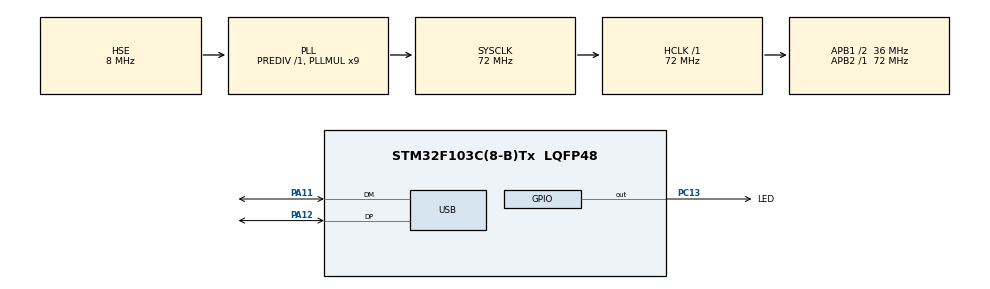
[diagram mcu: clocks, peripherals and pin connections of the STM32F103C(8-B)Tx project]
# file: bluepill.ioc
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FREERTOS.Tasks01=defaultTask,0,128,StartDefaultTask,Default,NULL
Mcu.Family=STM32F1
Mcu.Name=STM32F103C(8-B)Tx
Mcu.Package=LQFP48
NVIC.PriorityGroup=NVIC_PRIORITYGROUP_4
NVIC.TIM1_UP_IRQn=true\:0\:0\:false\:false\:true\:false\:false\:true
NVIC.TimeBase=TIM1_UP_IRQn
NVIC.TimeBaseIP=TIM1
NVIC.USB_LP_CAN1_RX0_IRQn=true\:5\:0\:false\:false\:true\:true\:false\:true
PA11.Mode=Device
PA11.Signal=USB_DM
PA12.Mode=Device
PA12.Signal=USB_DP
PC13-TAMPER-RTC.GPIO_Label=LED
PC13-TAMPER-RTC.Signal=GPIO_Output
PC14-OSC32_IN.Mode=LSE-External-Oscillator
PC14-OSC32_IN.Signal=RCC_OSC32_IN
PC15-OSC32_OUT.Mode=LSE-External-Oscillator
PC15-OSC32_OUT.Signal=RCC_OSC32_OUT
PD0-OSC_IN.Mode=HSE-External-Oscillator
PD0-OSC_IN.Signal=RCC_OSC_IN
PD1-OSC_OUT.Mode=HSE-External-Oscillator
PD1-OSC_OUT.Signal=RCC_OSC_OUT
ProjectManager.HeapSize=0x200
ProjectManager.StackSize=0x400
ProjectManager.TargetToolchain=Makefile
RCC.AHBFreq_Value=72000000
RCC.APB1CLKDivider=RCC_HCLK_DIV2
RCC.APB1Freq_Value=36000000
RCC.APB1TimFreq_Value=72000000
RCC.APB2Freq_Value=72000000
RCC.APB2TimFreq_Value=72000000
RCC.HCLKFreq_Value=72000000
RCC.PLLMUL=RCC_PLL_MUL9
RCC.PLLSourceVirtual=RCC_PLLSOURCE_HSE
RCC.SYSCLKFreq_VALUE=72000000
RCC.SYSCLKSource=RCC_SYSCLKSOURCE_PLLCLK
RCC.USBFreq_Value=48000000
RCC.USBPrescaler=RCC_USBCLKSOURCE_PLL_DIV1_5
USB_DEVICE.CLASS_NAME_FS=CDC
USB_DEVICE.USBD_DEBUG_LEVEL=2
USB_DEVICE.VirtualMode=Cdc
USB_DEVICE.VirtualModeFS=Cdc_FS
VP_FREERTOS_VS_CMSIS_V1.Mode=CMSIS_V1
VP_SYS_VS_ND.Mode=No_Debug
VP_SYS_VS_tim1.Mode=TIM1
VP_USB_DEVICE_VS_USB_DEVICE_CDC_FS.Mode=CDC_FS
board=custom

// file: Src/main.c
/* USER CODE BEGIN Header */
/**
  ******************************************************************************
  * @file           : main.c
  * @brief          : Main program body
  ******************************************************************************
  ** This notice applies to any and all portions of this file
  * that are not between comment pairs USER CODE BEGIN and
  * USER CODE END. Other portions of this file, whether
  * inserted by the user or by software development tools
  * are owned by their respective copyright owners.
  *
  * COPYRIGHT(c) 2019 STMicroelectronics
  *
  * Redistribution and use in source and binary forms, with or without modification,
  * are permitted provided that the following conditions are met:
  *   1. Redistributions of source code must retain the above copyright notice,
  *      this list of conditions and the following disclaimer.
  *   2. Redistributions in binary form must reproduce the above copyright notice,
  *      this list of conditions and the following disclaimer in the documentation
  *      and/or other materials provided with the distribution.
  *   3. Neither the name of STMicroelectronics nor the names of its contributors
  *      may be used to endorse or promote products derived from this software
  *      without specific prior written permission.
  *
  * THIS SOFTWARE IS PROVIDED BY THE COPYRIGHT HOLDERS AND CONTRIBUTORS "AS IS"
  * AND ANY EXPRESS OR IMPLIED WARRANTIES, INCLUDING, BUT NOT LIMITED TO, THE
  * IMPLIED WARRANTIES OF MERCHANTABILITY AND FITNESS FOR A PARTICULAR PURPOSE ARE
  * DISCLAIMED. IN NO EVENT SHALL THE COPYRIGHT HOLDER OR CONTRIBUTORS BE LIABLE
  * FOR ANY DIRECT, INDIRECT, INCIDENTAL, SPECIAL, EXEMPLARY, OR CONSEQUENTIAL
  * DAMAGES (INCLUDING, BUT NOT LIMITED TO, PROCUREMENT OF SUBSTITUTE GOODS OR
  * SERVICES; LOSS OF USE, DATA, OR PROFITS; OR BUSINESS INTERRUPTION) HOWEVER
  * CAUSED AND ON ANY THEORY OF LIABILITY, WHETHER IN CONTRACT, STRICT LIABILITY,
  * OR TORT (INCLUDING NEGLIGENCE OR OTHERWISE) ARISING IN ANY WAY OUT OF THE USE
  * OF THIS SOFTWARE, EVEN IF ADVISED OF THE POSSIBILITY OF SUCH DAMAGE.
  *
  ******************************************************************************
  */
/* USER CODE END Header */

#include "main.h"
#include "cmsis_os.h"
#include "usb_device.h"

osThreadId defaultTaskHandle;

void SystemClock_Config(void);
static void MX_GPIO_Init(void);
void StartDefaultTask(void const * argument);

int main(void)
{

  /* MCU Configuration--------------------------------------------------------*/

  /* Reset of all peripherals, Initializes the Flash interface and the Systick. */
  HAL_Init();

  /* Configure the system clock */
  SystemClock_Config();

  /* Initialize all configured peripherals */
  MX_GPIO_Init();

  /* Create the thread(s) */
  /* definition and creation of defaultTask */
  osThreadDef(defaultTask, StartDefaultTask, osPriorityNormal, 0, 128);
  defaultTaskHandle = osThreadCreate(osThread(defaultTask), NULL);

  /* Start scheduler */
  osKernelStart();

  /* We should never get here as control is now taken by the scheduler */

  /* Infinite loop */
  while (1)
  {

  }
}

void SystemClock_Config(void)
{
  RCC_OscInitTypeDef RCC_OscInitStruct = {0};
  RCC_ClkInitTypeDef RCC_ClkInitStruct = {0};
  RCC_PeriphCLKInitTypeDef PeriphClkInit = {0};

  /** Initializes the CPU, AHB and APB busses clocks
  */
  RCC_OscInitStruct.OscillatorType = RCC_OSCILLATORTYPE_HSE;
  RCC_OscInitStruct.HSEState = RCC_HSE_ON;
  RCC_OscInitStruct.HSEPredivValue = RCC_HSE_PREDIV_DIV1;
  RCC_OscInitStruct.HSIState = RCC_HSI_ON;
  RCC_OscInitStruct.PLL.PLLState = RCC_PLL_ON;
  RCC_OscInitStruct.PLL.PLLSource = RCC_PLLSOURCE_HSE;
  RCC_OscInitStruct.PLL.PLLMUL = RCC_PLL_MUL9;
  if (HAL_RCC_OscConfig(&RCC_OscInitStruct) != HAL_OK)
  {
    Error_Handler();
  }
  /** Initializes the CPU, AHB and APB busses clocks
  */
  RCC_ClkInitStruct.ClockType = RCC_CLOCKTYPE_HCLK|RCC_CLOCKTYPE_SYSCLK
                              |RCC_CLOCKTYPE_PCLK1|RCC_CLOCKTYPE_PCLK2;
  RCC_ClkInitStruct.SYSCLKSource = RCC_SYSCLKSOURCE_PLLCLK;
  RCC_ClkInitStruct.AHBCLKDivider = RCC_SYSCLK_DIV1;
  RCC_ClkInitStruct.APB1CLKDivider = RCC_HCLK_DIV2;
  RCC_ClkInitStruct.APB2CLKDivider = RCC_HCLK_DIV1;

  if (HAL_RCC_ClockConfig(&RCC_ClkInitStruct, FLASH_LATENCY_2) != HAL_OK)
  {
    Error_Handler();
  }
  PeriphClkInit.PeriphClockSelection = RCC_PERIPHCLK_USB;
  PeriphClkInit.UsbClockSelection = RCC_USBCLKSOURCE_PLL_DIV1_5;
  if (HAL_RCCEx_PeriphCLKConfig(&PeriphClkInit) != HAL_OK)
  {
    Error_Handler();
  }
}

static void MX_GPIO_Init(void)
{
  GPIO_InitTypeDef GPIO_InitStruct = {0};

  /* GPIO Ports Clock Enable */
  __HAL_RCC_GPIOC_CLK_ENABLE();
  __HAL_RCC_GPIOD_CLK_ENABLE();
  __HAL_RCC_GPIOA_CLK_ENABLE();

  /*Configure GPIO pin Output Level */
  HAL_GPIO_WritePin(LED_GPIO_Port, LED_Pin, GPIO_PIN_RESET);

  /*Configure GPIO pin : LED_Pin */
  GPIO_InitStruct.Pin = LED_Pin;
  GPIO_InitStruct.Mode = GPIO_MODE_OUTPUT_PP;
  GPIO_InitStruct.Pull = GPIO_NOPULL;
  GPIO_InitStruct.Speed = GPIO_SPEED_FREQ_LOW;
  HAL_GPIO_Init(LED_GPIO_Port, &GPIO_InitStruct);

}

void StartDefaultTask(void const * argument)
{
  /* init code for USB_DEVICE */
  MX_USB_DEVICE_Init();

  /* USER CODE BEGIN 5 */
  /* Infinite loop */
  char * greeting = "Hello World\r\n";
  for(;;)
  {
    HAL_GPIO_TogglePin(LED_GPIO_Port, LED_Pin);
    osDelay(1000);
    printf("%s",greeting);
  }
  /* USER CODE END 5 */
}

void HAL_TIM_PeriodElapsedCallback(TIM_HandleTypeDef *htim)
{
  if (htim->Instance == TIM1) {
    HAL_IncTick();
  }
}

void Error_Handler(void)
{
}

/************************ (C) COPYRIGHT STMicroelectronics *****END OF FILE****/
